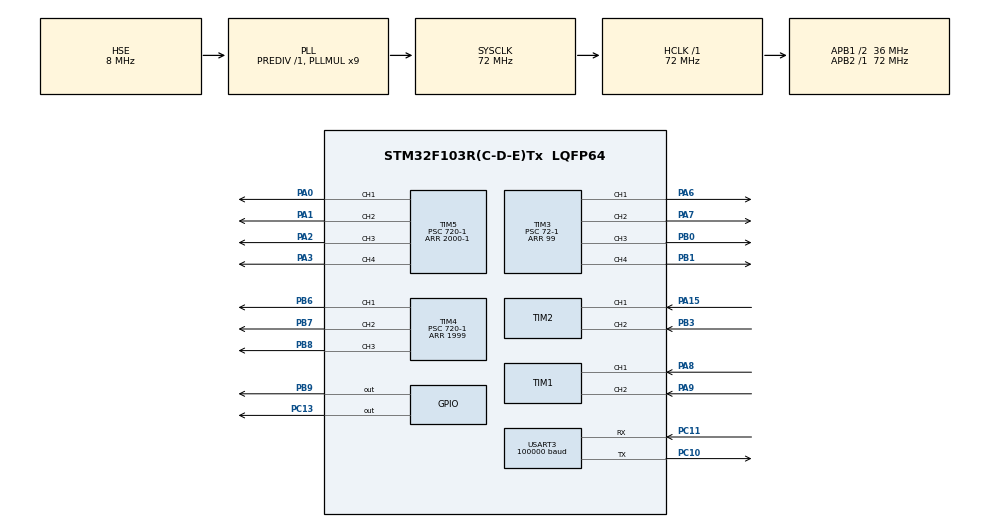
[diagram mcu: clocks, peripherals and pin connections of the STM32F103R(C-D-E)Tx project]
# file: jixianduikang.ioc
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Dma.Request0=USART3_RX
Dma.USART3_RX.0.Direction=DMA_PERIPH_TO_MEMORY
Dma.USART3_RX.0.Instance=DMA1_Channel3
Dma.USART3_RX.0.MemDataAlignment=DMA_MDATAALIGN_BYTE
Dma.USART3_RX.0.MemInc=DMA_MINC_ENABLE
Dma.USART3_RX.0.Mode=DMA_NORMAL
Dma.USART3_RX.0.PeriphDataAlignment=DMA_PDATAALIGN_BYTE
Dma.USART3_RX.0.PeriphInc=DMA_PINC_DISABLE
Dma.USART3_RX.0.Priority=DMA_PRIORITY_HIGH
Mcu.Family=STM32F1
Mcu.Name=STM32F103R(C-D-E)Tx
Mcu.Package=LQFP64
NVIC.DMA1_Channel3_IRQn=true\:0\:0\:false\:false\:true\:false\:true\:true
NVIC.PriorityGroup=NVIC_PRIORITYGROUP_4
NVIC.TIM6_IRQn=true\:0\:0\:false\:false\:true\:true\:true\:true
NVIC.TIM7_IRQn=true\:0\:0\:false\:false\:true\:true\:true\:true
NVIC.USART3_IRQn=true\:0\:0\:false\:false\:true\:true\:true\:true
PA0-WKUP.Signal=S_TIM5_CH1
PA1.Signal=S_TIM5_CH2
PA13.Mode=Serial_Wire
PA13.Signal=SYS_JTMS-SWDIO
PA14.Mode=Serial_Wire
PA14.Signal=SYS_JTCK-SWCLK
PA15.Signal=S_TIM2_CH1_ETR
PA2.Signal=S_TIM5_CH3
PA3.Signal=S_TIM5_CH4
PA6.Signal=S_TIM3_CH1
PA7.Signal=S_TIM3_CH2
PA8.Signal=S_TIM1_CH1
PA9.Signal=S_TIM1_CH2
PB0.Signal=S_TIM3_CH3
PB1.Signal=S_TIM3_CH4
PB3.Signal=S_TIM2_CH2
PB6.Signal=S_TIM4_CH1
PB7.Signal=S_TIM4_CH2
PB8.Signal=S_TIM4_CH3
PB9.Signal=GPIO_Output
PC10.Mode=Asynchronous
PC10.Signal=USART3_TX
PC11.Mode=Asynchronous
PC11.Signal=USART3_RX
PC13-TAMPER-RTC.Signal=GPIO_Output
PD0-OSC_IN.Mode=HSE-External-Oscillator
PD0-OSC_IN.Signal=RCC_OSC_IN
PD1-OSC_OUT.Mode=HSE-External-Oscillator
PD1-OSC_OUT.Signal=RCC_OSC_OUT
ProjectManager.HeapSize=0x200
ProjectManager.StackSize=0x400
ProjectManager.TargetToolchain=MDK-ARM V5.32
RCC.AHBFreq_Value=72000000
RCC.APB1CLKDivider=RCC_HCLK_DIV2
RCC.APB1Freq_Value=36000000
RCC.APB1TimFreq_Value=72000000
RCC.APB2Freq_Value=72000000
RCC.APB2TimFreq_Value=72000000
RCC.HCLKFreq_Value=72000000
RCC.PLLMUL=RCC_PLL_MUL9
RCC.PLLSourceVirtual=RCC_PLLSOURCE_HSE
RCC.SYSCLKFreq_VALUE=72000000
RCC.SYSCLKSource=RCC_SYSCLKSOURCE_PLLCLK
RCC.USBFreq_Value=72000000
SH.S_TIM1_CH1.0=TIM1_CH1,Encoder_Interface
SH.S_TIM1_CH2.0=TIM1_CH2,Encoder_Interface
SH.S_TIM2_CH1_ETR.0=TIM2_CH1,Encoder_Interface
SH.S_TIM2_CH2.0=TIM2_CH2,Encoder_Interface
SH.S_TIM3_CH1.0=TIM3_CH1,PWM Generation1 CH1
SH.S_TIM3_CH2.0=TIM3_CH2,PWM Generation2 CH2
SH.S_TIM3_CH3.0=TIM3_CH3,PWM Generation3 CH3
SH.S_TIM3_CH4.0=TIM3_CH4,PWM Generation4 CH4
SH.S_TIM4_CH1.0=TIM4_CH1,PWM Generation1 CH1
SH.S_TIM4_CH2.0=TIM4_CH2,PWM Generation2 CH2
SH.S_TIM4_CH3.0=TIM4_CH3,PWM Generation3 CH3
SH.S_TIM5_CH1.0=TIM5_CH1,PWM Generation1 CH1
SH.S_TIM5_CH2.0=TIM5_CH2,PWM Generation2 CH2
SH.S_TIM5_CH3.0=TIM5_CH3,PWM Generation3 CH3
SH.S_TIM5_CH4.0=TIM5_CH4,PWM Generation4 CH4
TIM1.EncoderMode=TIM_ENCODERMODE_TI12
TIM2.EncoderMode=TIM_ENCODERMODE_TI12
TIM3.Channel-PWM\ Generation1\ CH1=TIM_CHANNEL_1
TIM3.Channel-PWM\ Generation2\ CH2=TIM_CHANNEL_2
TIM3.Channel-PWM\ Generation3\ CH3=TIM_CHANNEL_3
TIM3.Channel-PWM\ Generation4\ CH4=TIM_CHANNEL_4
TIM3.Period=99
TIM3.Prescaler=72-1
TIM4.Channel-PWM\ Generation1\ CH1=TIM_CHANNEL_1
TIM4.Channel-PWM\ Generation2\ CH2=TIM_CHANNEL_2
TIM4.Channel-PWM\ Generation3\ CH3=TIM_CHANNEL_3
TIM4.Period=1999
TIM4.Prescaler=720-1
TIM5.Channel-PWM\ Generation1\ CH1=TIM_CHANNEL_1
TIM5.Channel-PWM\ Generation2\ CH2=TIM_CHANNEL_2
TIM5.Channel-PWM\ Generation3\ CH3=TIM_CHANNEL_3
TIM5.Channel-PWM\ Generation4\ CH4=TIM_CHANNEL_4
TIM5.Period=2000-1
TIM5.Prescaler=720-1
TIM6.Period=49
TIM6.Prescaler=7200-1
TIM7.Period=199
TIM7.Prescaler=7199
USART3.BaudRate=100000
USART3.Parity=PARITY_EVEN
USART3.VirtualMode=VM_ASYNC
USART3.WordLength=WORDLENGTH_9B
VP_TIM6_VS_ClockSourceINT.Mode=Enable_Timer
VP_TIM7_VS_ClockSourceINT.Mode=Enable_Timer
board=custom

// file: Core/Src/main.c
/* USER CODE BEGIN Header */
/**
  ******************************************************************************
  * @file           : main.c
  * @brief          : Main program body
  ******************************************************************************
  * @attention
  *
  * Copyright (c) 2024 STMicroelectronics.
  * All rights reserved.
  *
  * This software is licensed under terms that can be found in the LICENSE file
  * in the root directory of this software component.
  * If no LICENSE file comes with this software, it is provided AS-IS.
  *
  ******************************************************************************
  */
/* USER CODE END Header */
#include "main.h"
#include "dma.h"
#include "tim.h"
#include "usart.h"
#include "gpio.h"

/* USER CODE BEGIN Includes */
#include "bsp_tim.h"
#include "bsp_uart.h"
#include "pid.h"
#include "motor.h"
#include <stdio.h>
#include "string.h"
/* USER CODE END Includes */

void SystemClock_Config(void);

int main(void)
{

  /* MCU Configuration--------------------------------------------------------*/

  /* Reset of all peripherals, Initializes the Flash interface and the Systick. */
  HAL_Init();

  /* Configure the system clock */
  SystemClock_Config();

  /* Initialize all configured peripherals */
  MX_GPIO_Init();
  MX_DMA_Init();
  MX_TIM1_Init();
  MX_TIM2_Init();
  MX_USART3_UART_Init();
  MX_TIM3_Init();
  MX_TIM6_Init();
  MX_TIM4_Init();
  MX_TIM5_Init();
  MX_TIM7_Init();
  /* USER CODE BEGIN 2 */
       HAL_Delay(500);
       Encoder_Init();
       HAL_UART_Receive_DMA(&huart3, (uint8_t *)aRxBuffer1, RXBUFFERSIZE);
	   PID_int();
       HAL_GPIO_WritePin(GPIOC, GPIO_PIN_13, GPIO_PIN_SET);
  /* USER CODE END 2 */

  /* Infinite loop */
  /* USER CODE BEGIN WHILE */
  while (1)
  {

//
//      printf("%d,%d\r\n",motor[0].speed, wheel_rpm[0]);
//      HAL_Delay(10);
//      HAL_GPIO_WritePin(GPIOC, GPIO_PIN_13, GPIO_PIN_SET);
//      HAL_Delay(1000);
//       HAL_GPIO_WritePin(GPIOC, GPIO_PIN_13, GPIO_PIN_RESET);
//      HAL_Delay(1000)
    /* USER CODE END WHILE */

  }
}

void SystemClock_Config(void)
{
  RCC_OscInitTypeDef RCC_OscInitStruct = {0};
  RCC_ClkInitTypeDef RCC_ClkInitStruct = {0};

  /** Initializes the RCC Oscillators according to the specified parameters
  * in the RCC_OscInitTypeDef structure.
  */
  RCC_OscInitStruct.OscillatorType = RCC_OSCILLATORTYPE_HSE;
  RCC_OscInitStruct.HSEState = RCC_HSE_ON;
  RCC_OscInitStruct.HSEPredivValue = RCC_HSE_PREDIV_DIV1;
  RCC_OscInitStruct.HSIState = RCC_HSI_ON;
  RCC_OscInitStruct.PLL.PLLState = RCC_PLL_ON;
  RCC_OscInitStruct.PLL.PLLSource = RCC_PLLSOURCE_HSE;
  RCC_OscInitStruct.PLL.PLLMUL = RCC_PLL_MUL9;
  if (HAL_RCC_OscConfig(&RCC_OscInitStruct) != HAL_OK)
  {
    Error_Handler();
  }

  /** Initializes the CPU, AHB and APB buses clocks
  */
  RCC_ClkInitStruct.ClockType = RCC_CLOCKTYPE_HCLK|RCC_CLOCKTYPE_SYSCLK
                              |RCC_CLOCKTYPE_PCLK1|RCC_CLOCKTYPE_PCLK2;
  RCC_ClkInitStruct.SYSCLKSource = RCC_SYSCLKSOURCE_PLLCLK;
  RCC_ClkInitStruct.AHBCLKDivider = RCC_SYSCLK_DIV1;
  RCC_ClkInitStruct.APB1CLKDivider = RCC_HCLK_DIV2;
  RCC_ClkInitStruct.APB2CLKDivider = RCC_HCLK_DIV1;

  if (HAL_RCC_ClockConfig(&RCC_ClkInitStruct, FLASH_LATENCY_2) != HAL_OK)
  {
    Error_Handler();
  }
}

void Error_Handler(void)
{
  __disable_irq();
  while (1)
  {
  }
}
